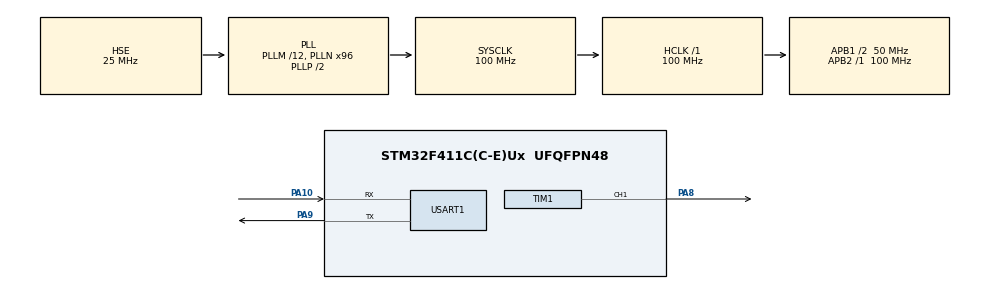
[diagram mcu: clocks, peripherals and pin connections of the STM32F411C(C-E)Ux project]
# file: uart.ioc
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Mcu.Family=STM32F4
Mcu.Name=STM32F411C(C-E)Ux
Mcu.Package=UFQFPN48
NVIC.PriorityGroup=NVIC_PRIORITYGROUP_4
NVIC.USART1_IRQn=true\:0\:0\:false\:false\:true\:true\:true\:true
PA10.Mode=Asynchronous
PA10.Signal=USART1_RX
PA13.Mode=Serial_Wire
PA13.Signal=SYS_JTMS-SWDIO
PA14.Mode=Serial_Wire
PA14.Signal=SYS_JTCK-SWCLK
PA8.Signal=S_TIM1_CH1
PA9.Mode=Asynchronous
PA9.Signal=USART1_TX
PH0\ -\ OSC_IN.Mode=HSE-External-Oscillator
PH0\ -\ OSC_IN.Signal=RCC_OSC_IN
PH1\ -\ OSC_OUT.Mode=HSE-External-Oscillator
PH1\ -\ OSC_OUT.Signal=RCC_OSC_OUT
ProjectManager.HeapSize=0x200
ProjectManager.StackSize=0x400
ProjectManager.TargetToolchain=Makefile
RCC.48MHZClocksFreq_Value=50000000
RCC.AHBFreq_Value=100000000
RCC.APB1CLKDivider=RCC_HCLK_DIV2
RCC.APB1Freq_Value=50000000
RCC.APB1TimFreq_Value=100000000
RCC.APB2Freq_Value=100000000
RCC.APB2TimFreq_Value=100000000
RCC.CortexFreq_Value=100000000
RCC.HCLKFreq_Value=100000000
RCC.HSE_VALUE=25000000
RCC.HSI_VALUE=16000000
RCC.LSE_VALUE=32768
RCC.PLLM=12
RCC.PLLN=96
RCC.PLLSourceVirtual=RCC_PLLSOURCE_HSE
RCC.SYSCLKFreq_VALUE=100000000
RCC.SYSCLKSource=RCC_SYSCLKSOURCE_PLLCLK
RCC.VCOOutputFreq_Value=200000000
SH.S_TIM1_CH1.0=TIM1_CH1,PWM Generation1 CH1
TIM1.Channel-PWM\ Generation1\ CH1=TIM_CHANNEL_1
TIM1.OCFastMode_PWM-PWM\ Generation1\ CH1=TIM_OCFAST_ENABLE
TIM1.Period=3999
USART1.VirtualMode=VM_ASYNC
board=custom

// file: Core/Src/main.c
/* USER CODE BEGIN Header */
/**
  ******************************************************************************
  * @file           : main.c
  * @brief          : Main program body
  ******************************************************************************
  * @attention
  *
  * Copyright (c) 2026 STMicroelectronics.
  * All rights reserved.
  *
  * This software is licensed under terms that can be found in the LICENSE file
  * in the root directory of this software component.
  * If no LICENSE file comes with this software, it is provided AS-IS.
  *
  ******************************************************************************
  */
/* USER CODE END Header */
#include "main.h"

/* USER CODE BEGIN Includes */
#include <string.h>
#include <stdio.h>
/* USER CODE END Includes */

TIM_HandleTypeDef htim1;

UART_HandleTypeDef huart1;

/* USER CODE BEGIN PV */
uint8_t rx_buffer[16];
uint8_t rx_index = 0;
/* USER CODE END PV */

void SystemClock_Config(void);
static void MX_GPIO_Init(void);
static void MX_USART1_UART_Init(void);
static void MX_TIM1_Init(void);

/* USER CODE BEGIN 0 */
void process_uart_command(void)
{
    // Проверяем, что команда начинается с 'd'
    if(rx_buffer[0] == 'd' || rx_buffer[0] == 'D')
    {
        char *ptr = (char*)rx_buffer;
        int value = 0;

        // Пропускаем 'd'
        ptr++;

        // Пропускаем пробелы
        while(*ptr == ' ') ptr++;

        // Парсим число
        while(*ptr >= '0' && *ptr <= '9')
        {
            value = value * 10 + (*ptr - '0');
            ptr++;
        }

        // Ограничиваем значение
        if(value > 1999) value = 1999;

        // Устанавливаем PWM
        TIM1->CCR1 = value;

        // Отправляем подтверждение
        char response[32];
        sprintf(response, "OK: %d\r\n", value);
        HAL_UART_Transmit(&huart1, (uint8_t*)response, strlen(response), 100);
    }

    // Очищаем буфер
    memset(rx_buffer, 0, sizeof(rx_buffer));
    rx_index = 0;
}

void HAL_UART_RxCpltCallback(UART_HandleTypeDef *huart)
{
    if(huart->Instance == USART1)
    {
        // Если Enter - обрабатываем команду
        if(rx_buffer[rx_index] == '\r' || rx_buffer[rx_index] == '\n')
        {
            rx_buffer[rx_index] = '\0';
            process_uart_command();
            HAL_UART_Transmit(&huart1, (uint8_t*)"\r\n> ", 4, 100);
            rx_index = 0;
            HAL_UART_Receive_IT(&huart1, &rx_buffer[0], 1);
        }
        else if(rx_index < sizeof(rx_buffer) - 1)
        {
            rx_index++;
            HAL_UART_Receive_IT(&huart1, &rx_buffer[rx_index], 1);
        }
        else
        {
            // Переполнение - сброс
            rx_index = 0;
            memset(rx_buffer, 0, sizeof(rx_buffer));
            HAL_UART_Receive_IT(&huart1, &rx_buffer[0], 1);
        }
    }
}
/* USER CODE END 0 */

int main(void)
{
  HAL_Init();
  SystemClock_Config();
  MX_GPIO_Init();
  MX_USART1_UART_Init();
  MX_TIM1_Init();

  /* USER CODE BEGIN 2 */
  // Запускаем прием
  HAL_UART_Receive_IT(&huart1, &rx_buffer[0], 1);

  // Запускаем PWM
  HAL_TIM_PWM_Start(&htim1, TIM_CHANNEL_1);
  TIM1->CCR1 = 0;

  // Приветствие
  HAL_UART_Transmit(&huart1, (uint8_t*)"\r\nPWM Control\r\n", 15, 100);
  HAL_UART_Transmit(&huart1, (uint8_t*)"Command: d <0-1999>\r\n", 21, 100);
  HAL_UART_Transmit(&huart1, (uint8_t*)"\r\n> ", 4, 100);
  /* USER CODE END 2 */

  while (1)
  {
  }
}

void SystemClock_Config(void)
{
  RCC_OscInitTypeDef RCC_OscInitStruct = {0};
  RCC_ClkInitTypeDef RCC_ClkInitStruct = {0};

  /** Configure the main internal regulator output voltage
  */
  __HAL_RCC_PWR_CLK_ENABLE();
  __HAL_PWR_VOLTAGESCALING_CONFIG(PWR_REGULATOR_VOLTAGE_SCALE1);

  /** Initializes the RCC Oscillators according to the specified parameters
  * in the RCC_OscInitTypeDef structure.
  */
  RCC_OscInitStruct.OscillatorType = RCC_OSCILLATORTYPE_HSE;
  RCC_OscInitStruct.HSEState = RCC_HSE_ON;
  RCC_OscInitStruct.PLL.PLLState = RCC_PLL_ON;
  RCC_OscInitStruct.PLL.PLLSource = RCC_PLLSOURCE_HSE;
  RCC_OscInitStruct.PLL.PLLM = 12;
  RCC_OscInitStruct.PLL.PLLN = 96;
  RCC_OscInitStruct.PLL.PLLP = RCC_PLLP_DIV2;
  RCC_OscInitStruct.PLL.PLLQ = 4;
  if (HAL_RCC_OscConfig(&RCC_OscInitStruct) != HAL_OK)
  {
    Error_Handler();
  }

  /** Initializes the CPU, AHB and APB buses clocks
  */
  RCC_ClkInitStruct.ClockType = RCC_CLOCKTYPE_HCLK|RCC_CLOCKTYPE_SYSCLK
                              |RCC_CLOCKTYPE_PCLK1|RCC_CLOCKTYPE_PCLK2;
  RCC_ClkInitStruct.SYSCLKSource = RCC_SYSCLKSOURCE_PLLCLK;
  RCC_ClkInitStruct.AHBCLKDivider = RCC_SYSCLK_DIV1;
  RCC_ClkInitStruct.APB1CLKDivider = RCC_HCLK_DIV2;
  RCC_ClkInitStruct.APB2CLKDivider = RCC_HCLK_DIV1;

  if (HAL_RCC_ClockConfig(&RCC_ClkInitStruct, FLASH_LATENCY_3) != HAL_OK)
  {
    Error_Handler();
  }
}

static void MX_TIM1_Init(void)
{

  TIM_MasterConfigTypeDef sMasterConfig = {0};
  TIM_OC_InitTypeDef sConfigOC = {0};
  TIM_BreakDeadTimeConfigTypeDef sBreakDeadTimeConfig = {0};

  htim1.Instance = TIM1;
  htim1.Init.Prescaler = 0;
  htim1.Init.CounterMode = TIM_COUNTERMODE_UP;
  htim1.Init.Period = 2000-1;
  htim1.Init.ClockDivision = TIM_CLOCKDIVISION_DIV1;
  htim1.Init.RepetitionCounter = 0;
  htim1.Init.AutoReloadPreload = TIM_AUTORELOAD_PRELOAD_DISABLE;
  if (HAL_TIM_PWM_Init(&htim1) != HAL_OK)
  {
    Error_Handler();
  }
  sMasterConfig.MasterOutputTrigger = TIM_TRGO_RESET;
  sMasterConfig.MasterSlaveMode = TIM_MASTERSLAVEMODE_DISABLE;
  if (HAL_TIMEx_MasterConfigSynchronization(&htim1, &sMasterConfig) != HAL_OK)
  {
    Error_Handler();
  }
  sConfigOC.OCMode = TIM_OCMODE_PWM1;
  sConfigOC.Pulse = 0;
  sConfigOC.OCPolarity = TIM_OCPOLARITY_HIGH;
  sConfigOC.OCNPolarity = TIM_OCNPOLARITY_HIGH;
  sConfigOC.OCFastMode = TIM_OCFAST_ENABLE;
  sConfigOC.OCIdleState = TIM_OCIDLESTATE_RESET;
  sConfigOC.OCNIdleState = TIM_OCNIDLESTATE_RESET;
  if (HAL_TIM_PWM_ConfigChannel(&htim1, &sConfigOC, TIM_CHANNEL_1) != HAL_OK)
  {
    Error_Handler();
  }
  sBreakDeadTimeConfig.OffStateRunMode = TIM_OSSR_DISABLE;
  sBreakDeadTimeConfig.OffStateIDLEMode = TIM_OSSI_DISABLE;
  sBreakDeadTimeConfig.LockLevel = TIM_LOCKLEVEL_OFF;
  sBreakDeadTimeConfig.DeadTime = 0;
  sBreakDeadTimeConfig.BreakState = TIM_BREAK_DISABLE;
  sBreakDeadTimeConfig.BreakPolarity = TIM_BREAKPOLARITY_HIGH;
  sBreakDeadTimeConfig.AutomaticOutput = TIM_AUTOMATICOUTPUT_DISABLE;
  if (HAL_TIMEx_ConfigBreakDeadTime(&htim1, &sBreakDeadTimeConfig) != HAL_OK)
  {
    Error_Handler();
  }
  HAL_TIM_MspPostInit(&htim1);
  //ban
}

static void MX_USART1_UART_Init(void)
{

  huart1.Instance = USART1;
  huart1.Init.BaudRate = 115200;
  huart1.Init.WordLength = UART_WORDLENGTH_8B;
  huart1.Init.StopBits = UART_STOPBITS_1;
  huart1.Init.Parity = UART_PARITY_NONE;
  huart1.Init.Mode = UART_MODE_TX_RX;
  huart1.Init.HwFlowCtl = UART_HWCONTROL_NONE;
  huart1.Init.OverSampling = UART_OVERSAMPLING_16;
  if (HAL_UART_Init(&huart1) != HAL_OK)
  {
    Error_Handler();
  }

}

static void MX_GPIO_Init(void)
{
  /* USER CODE BEGIN MX_GPIO_Init_1 */
  GPIO_InitTypeDef GPIO_InitStruct = {0};
  /* USER CODE END MX_GPIO_Init_1 */

  /* GPIO Ports Clock Enable */
  __HAL_RCC_GPIOH_CLK_ENABLE();
  __HAL_RCC_GPIOA_CLK_ENABLE();
  __HAL_RCC_GPIOB_CLK_ENABLE();

  /* Настройка пина для TIM1_CH1 (PA8) - PWM вывод */
  GPIO_InitStruct.Pin = GPIO_PIN_8;
  GPIO_InitStruct.Mode = GPIO_MODE_AF_PP;
  GPIO_InitStruct.Pull = GPIO_NOPULL;
  GPIO_InitStruct.Speed = GPIO_SPEED_FREQ_HIGH;
  GPIO_InitStruct.Alternate = GPIO_AF1_TIM1;  // Для STM32F411 TIM1 на AF1
  HAL_GPIO_Init(GPIOA, &GPIO_InitStruct);

  /* Настройка пинов для USART1 (PA9 - TX, PA10 - RX) */
  GPIO_InitStruct.Pin = GPIO_PIN_9 | GPIO_PIN_10;
  GPIO_InitStruct.Mode = GPIO_MODE_AF_PP;
  GPIO_InitStruct.Pull = GPIO_NOPULL;
  GPIO_InitStruct.Speed = GPIO_SPEED_FREQ_HIGH;
  GPIO_InitStruct.Alternate = GPIO_AF7_USART1;  // Для STM32F411 USART1 на AF7
  HAL_GPIO_Init(GPIOA, &GPIO_InitStruct);

}

/* USER CODE BEGIN 4 */
/**
  * @brief  UART error callback (обработка ошибок UART)
  * @param  huart UART handle
  * @retval None
  */
void HAL_UART_ErrorCallback(UART_HandleTypeDef *huart)
{
  if(huart->Instance == USART1)
  {
    // Очищаем флаги ошибок
    __HAL_UART_CLEAR_FLAG(huart, UART_FLAG_ORE);  // Overrun error
    __HAL_UART_CLEAR_FLAG(huart, UART_FLAG_NE);   // Noise error
    __HAL_UART_CLEAR_FLAG(huart, UART_FLAG_FE);   // Framing error
    __HAL_UART_CLEAR_FLAG(huart, UART_FLAG_PE);   // Parity error

    // Перезапускаем прием
    rx_index = 0;
    memset(rx_buffer, 0, sizeof(rx_buffer));
    HAL_UART_Transmit(&huart1, (uint8_t*)"\r\nUART Error! Resetting...\r\n> ", 31, 100);
    HAL_UART_Receive_IT(&huart1, &rx_buffer[0], 1);
  }
}
/* USER CODE END 4 */

void Error_Handler(void)
{
  __disable_irq();
  while (1)
  {
  }
}
